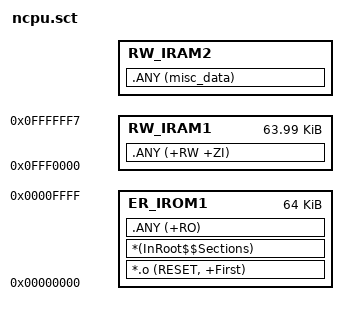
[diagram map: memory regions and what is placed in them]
#!armcc -E
#define DRAM_START 0x0FFF0000
#define DRAM_SIZE  0x00010000

LR_IROM1 0x00000000 0x00010000  {    ; load region size_region
  ER_IROM1 0x00000000 0x00010000  {  ; load address = execution address
   *.o (RESET, +First)
   *(InRoot$$Sections)
   .ANY (+RO)
  }
  RW_IRAM1 DRAM_START DRAM_SIZE-8  {  ; RW data
   .ANY (+RW +ZI)
  }

  RW_IRAM2 AlignExpr(+0,8)  {
   .ANY (misc_data)
  }
}

